# M369 register map
File version: 0.1
Registers are 32-bit, read-write, reset 0x0 unless marked. A register's access mark holds for its fields unless they carry their own. Offsets are from the block's base; [hi:lo] are bit positions; {n}, {i} and the like mark numbered series; 'fields as' and 'values as' point back to an identical list.

## CANMB0 — CAN Controller (TXCAN) Mailbox RAM
Base 0x40005000
Same registers: CANMB{n} {0x40005000+0x20*n} (n=1..30)
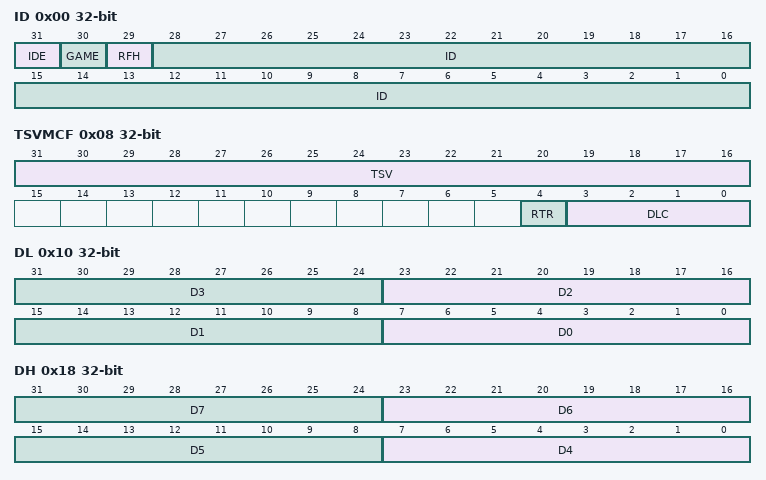
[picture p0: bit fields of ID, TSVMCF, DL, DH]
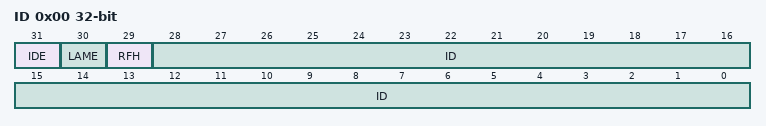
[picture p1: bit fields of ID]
0x00 ID reset not defined — CAN Mailbox Register
  [31] IDE, [30] GAME, [29] RFH, [28:0] ID
0x08 TSVMCF reset not defined — CAN Mailbox Register
  [31:16] TSV, [4] RTR, [3:0] DLC
0x10 DL reset not defined — CAN Mailbox Register
  [8n+7:8n] D{n} (n=0..3)
0x18 DH reset not defined — CAN Mailbox Register
  [8n-25:8n-32] D{n} (n=4..7)

## CANMB31 — CAN Controller (TXCAN) Mailbox RAM
Base 0x400053E0
Registers as CANMB0; these are added or differ:
0x00 ID reset not defined — CAN Mailbox Register
  [31] IDE, [30] LAME, [29] RFH, [28:0] ID

## CAN — CAN Controller (TXCAN)
Base 0x40005400
0x00 MC — CAN Mailbox Configuration Register
0x08 MD — CAN Mailbox Direction Register
0x10 TRS — CAN Transmit Request Set Register
  [30:0] TRS
0x18 TRR — CAN Transmit Request Reset Register
  [30:0] TRR
0x20 TA — CAN Transmission Acknowledge Register
  [30:0] TA
0x28 AA — CAN Abort Acknowledge Register
  [30:0] AA
0x30 RMP — CAN Receive Message Pending Register
0x38 RML — CAN Receive Message Lost Register
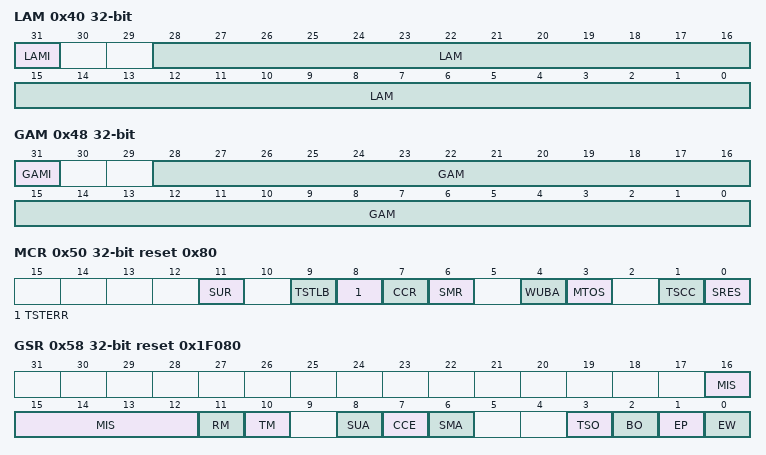
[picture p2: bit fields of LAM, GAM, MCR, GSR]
0x40 LAM — CAN Local Acceptance Mask Register
  [31] LAMI, [28:0] LAM
0x48 GAM — CAN Global Acceptance Mask Register
  [31] GAMI, [28:0] GAM
0x50 MCR reset 0x80 — CAN Master Control Register
  [11] SUR, [9] TSTLB, [8] TSTERR, [7] CCR, [6] SMR, [4] WUBA, [3] MTOS, [1] TSCC, [0] SRES
0x58 GSR ro reset 0x1F080 — CAN Global Status Register
  [16:12] MIS, [11] RM, [10] TM, [8] SUA, [7] CCE, [6] SMA, [3] TSO, [2] BO, [1] EP, [0] EW
0x60 BCR1 — CAN Bit Configuration Register 1
  [9:0] BRP
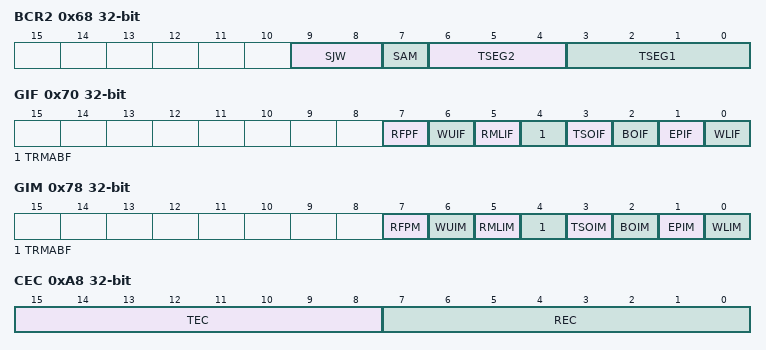
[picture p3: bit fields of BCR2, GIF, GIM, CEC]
0x68 BCR2 — CAN Bit Configuration Register 2
  [9:8] SJW, [7] SAM, [6:4] TSEG2, [3:0] TSEG1
0x70 GIF — CAN Global Interrupt Flag Register
  [7] RFPF, [6] WUIF, [5] RMLIF, [4] TRMABF, [3] TSOIF, [2] BOIF, [1] EPIF, [0] WLIF
0x78 GIM — CAN Global Interrupt Mask Register
  [7] RFPM, [6] WUIM, [5] RMLIM, [4] TRMABF, [3] TSOIM, [2] BOIM, [1] EPIM, [0] WLIM
0x80 MBTIF — CAN Mailbox Transmit Interrupt Flag Register
  [30:0] MBTIF
0x88 MBRIF — CAN Mailbox Receive Interrupt Flag Register
0x90 MBIM — CAN Mailbox Interrupt Mask Register
0x98 CDR — CAN Change Data Request
  [30:0] CDR
0xA0 RFP — CAN Remote Frame Pending Register
0xA8 CEC — CAN Error Counter Register
  [15:8] TEC ro, [7:0] REC ro
0xB0 TSP — CAN Time Stamp Counter Prescaler Register
  [3:0] TSP
0xB8 TSC — CAN Time Stamp Counter Register
  [15:0] TSC

## HC — USB Host Controller (USBHC)
Base 0x40006000
0x00 REVISION ro reset 0x10 — USB Host Controller Revision Register
  [7:0] REV
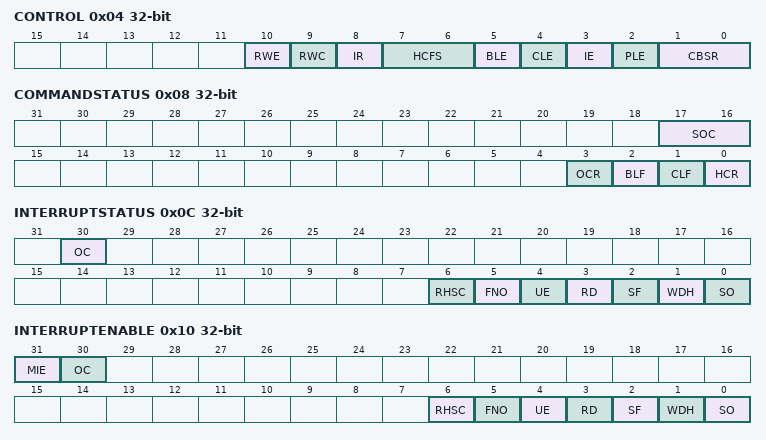
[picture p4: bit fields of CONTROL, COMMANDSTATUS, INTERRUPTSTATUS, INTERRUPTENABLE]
0x04 CONTROL — USB Host Controller Control Register
  [10] RWE, [9] RWC, [8] IR, [7:6] HCFS, [5] BLE, [4] CLE, [3] IE, [2] PLE, [1:0] CBSR
0x08 COMMANDSTATUS — USB Host Controller Command Status Register
  [17:16] SOC ro, [3] OCR, [2] BLF, [1] CLF, [0] HCR
0x0C INTERRUPTSTATUS — USB Host Controller Interrupt Status Register
  [30] OC, [6] RHSC, [5] FNO, [4] UE, [3] RD, [2] SF, [1] WDH, [0] SO
0x10 INTERRUPTENABLE — USB Host Controller Interrupt Enable Register
  [31] MIE, [30] OC, [6] RHSC, [5] FNO, [4] UE, [3] RD, [2] SF, [1] WDH, [0] SO
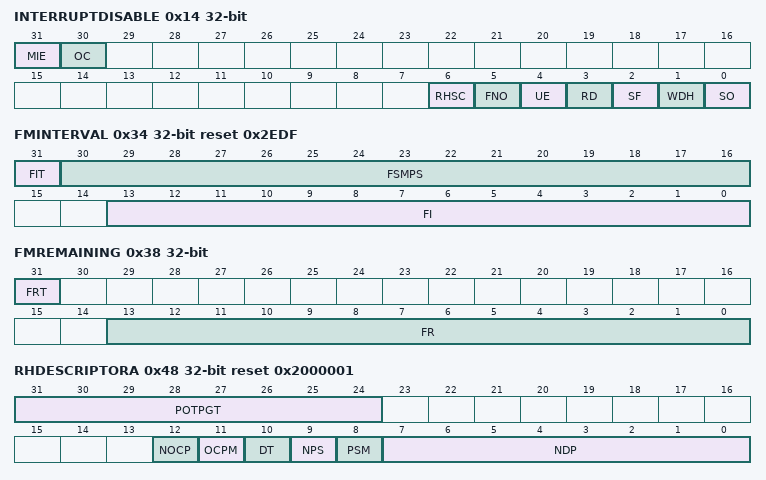
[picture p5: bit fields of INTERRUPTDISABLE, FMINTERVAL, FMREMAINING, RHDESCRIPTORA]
0x14 INTERRUPTDISABLE — USB Host Controller Interrupt Disable Register
  fields as INTERRUPTENABLE
0x18 HCCA — USB Host Controller Communication Area Register
  [31:8] HCCA
0x1C PERIODCURRENTED ro — USB Host Controller Period Current ED Register
  [31:4] PCED
0x20 CONTROLHEADED — USB Host Controller Control Head ED Register
  [31:4] CHED
0x24 CONTROLCURRENTED — USB Host Controller Control Current ED Register
  [31:4] CCED
0x28 BULKHEADED — USB Host Controller Bulk Head ED Register
  [31:4] BHED
0x2C BULKCURRENTED — USB Host Controller Bulk Current ED Register
  [31:4] BCED
0x30 DONEHEAD ro — USB Host Controller Done Head Register
  [31:4] DH
0x34 FMINTERVAL reset 0x2EDF (reset mask 0x80003FFF) — USB Host Controller Frame Interval Register
  [31] FIT, [30:16] FSMPS, [13:0] FI
0x38 FMREMAINING ro — USB Host Controller Frame Remaining Register
  [31] FRT, [13:0] FR
0x3C FMNUMBER ro — USB Host Controller Frame Number Register
  [15:0] FN
0x40 PERIODSTART — USB Host Controller Period Start Register
  [13:0] PS
0x44 LSTHRESHOLD reset 0x628 — USB Host Controller LS Threshold Register
  [11:0] LST
0x48 RHDESCRIPTORA reset 0x2000001 — USB Host Controller Root Hub Descriptor Register
  [31:24] POTPGT, [12] NOCP, [11] OCPM, [10] DT ro, [9] NPS, [8] PSM, [7:0] NDP ro
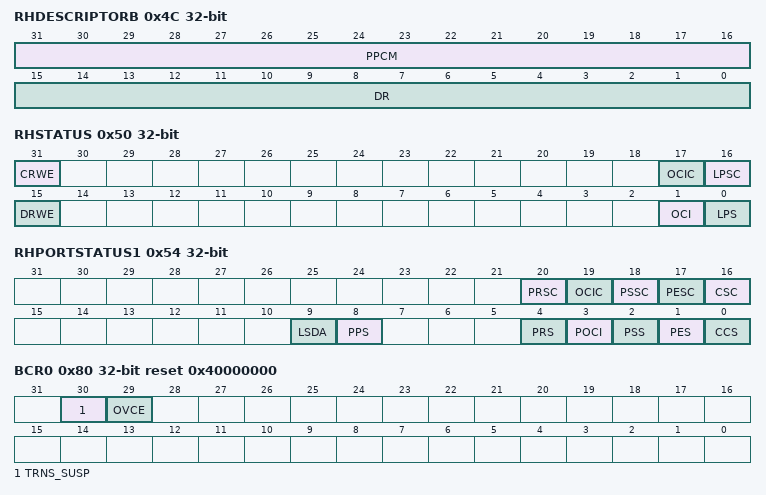
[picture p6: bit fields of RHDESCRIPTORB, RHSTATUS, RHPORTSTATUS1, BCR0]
0x4C RHDESCRIPTORB — USB Host Controller Root Hub Descriptor Register
  [31:16] PPCM, [15:0] DR
0x50 RHSTATUS (reset mask 0x38003) — USB Host Controller Root Hub Status Register
  [31] CRWE wo, [17] OCIC, [16] LPSC, [15] DRWE, [1] OCI ro, [0] LPS
0x54 RHPORTSTATUS1 (reset mask 0x1F011F) — USB Host Controller Root Hub Port Status Register
  [20] PRSC, [19] OCIC, [18] PSSC, [17] PESC, [16] CSC, [9] LSDA, [8] PPS, [4] PRS, [3] POCI, [2] PSS, [1] PES, [0] CCS
0x80 BCR0 reset 0x40000000 — USB Host Controller Clock and Transceiver Control Register
  [30] TRNS_SUSP, [29] OVCE
